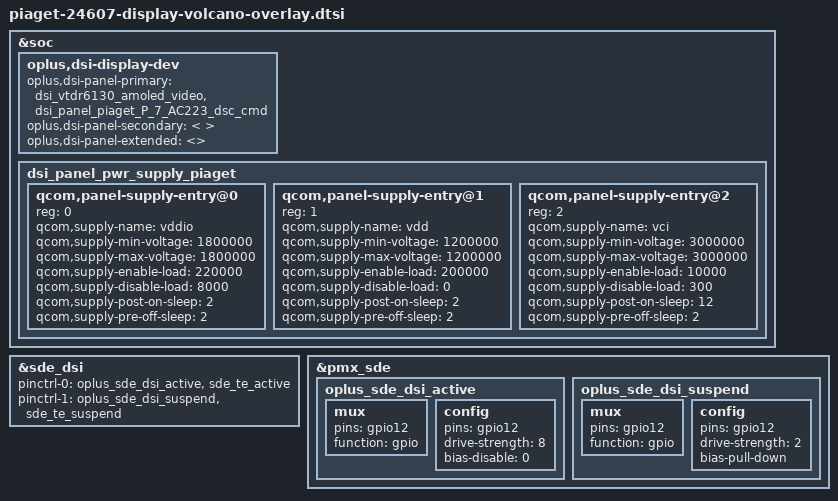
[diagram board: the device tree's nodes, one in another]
#include "panel/dsi_panel_piaget_P_7_AC223_dsc_cmd.dtsi"

&soc {
	oplus,dsi-display-dev {
		oplus,dsi-panel-primary = <
			&dsi_vtdr6130_amoled_video
			&dsi_panel_piaget_P_7_AC223_dsc_cmd
		>;
		oplus,dsi-panel-secondary = <
		>;
		oplus,dsi-panel-extended = <>;
	};


	dsi_panel_pwr_supply_piaget: dsi_panel_pwr_supply_piaget {
		#address-cells = <1>;
		#size-cells = <0>;

		qcom,panel-supply-entry@0 {
			reg = <0>;
			qcom,supply-name = "vddio";
			qcom,supply-min-voltage = <1800000>;
			qcom,supply-max-voltage = <1800000>;
			qcom,supply-enable-load = <220000>;
			qcom,supply-disable-load = <8000>;
			qcom,supply-post-on-sleep = <2>;
			qcom,supply-pre-off-sleep = <2>;
		};

		qcom,panel-supply-entry@1 {
			reg = <1>;
			qcom,supply-name = "vdd";
			qcom,supply-min-voltage = <1200000>;
			qcom,supply-max-voltage = <1200000>;
			qcom,supply-enable-load = <200000>;
			qcom,supply-disable-load = <0>;
			qcom,supply-post-on-sleep = <2>;
			qcom,supply-pre-off-sleep = <2>;
		};

		qcom,panel-supply-entry@2 {
			reg = <2>;
			qcom,supply-name = "vci";
			qcom,supply-min-voltage = <3000000>;
			qcom,supply-max-voltage = <3000000>;
			qcom,supply-enable-load = <10000>;
			qcom,supply-disable-load = <300>;
			qcom,supply-post-on-sleep = <12>;
			qcom,supply-pre-off-sleep = <2>;
		};
	};
};

&sde_dsi {
	pinctrl-names = "panel_active", "panel_suspend";
	pinctrl-0 = <&oplus_sde_dsi_active &sde_te_active>;
	pinctrl-1 = <&oplus_sde_dsi_suspend &sde_te_suspend>;
};

&pmx_sde {
	oplus_sde_dsi_active: oplus_sde_dsi_active {
		mux {
			pins = "gpio12";
			function = "gpio";
		};

		config {
			pins = "gpio12";
			drive-strength = <8>;   /* 8 mA */
			bias-disable = <0>;   /* no pull */
		};
	};

	oplus_sde_dsi_suspend: oplus_sde_dsi_suspend {
		mux {
			pins = "gpio12";
			function = "gpio";
		};

		config {
			pins = "gpio12";
			drive-strength = <2>;   /* 2 mA */
			bias-pull-down;         /* PULL DOWN */
		};
	};
};
